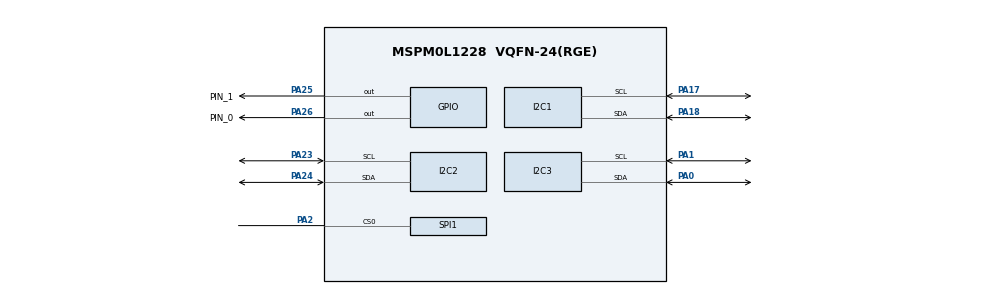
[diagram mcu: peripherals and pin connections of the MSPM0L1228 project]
/**
 * These arguments were used when this file was generated. They will be automatically applied on subsequent loads
 * via the GUI or CLI. Run CLI with '--help' for additional information on how to override these arguments.
 * @cliArgs --device "MSPM0L122X" --part "Default" --package "VQFN-24(RGE)" --product "mspm0_sdk@2.10.00.04"
 * @v2CliArgs --device "MSPM0L1228" --package "VQFN-24(RGE)" --product "mspm0_sdk@2.10.00.04"
 * @versions {"tool":"1.26.2+4477"}
 */

/**
 * Import the modules used in this configuration.
 */
const GPIO   = scripting.addModule("/ti/driverlib/GPIO", {}, false);
const GPIO1  = GPIO.addInstance();
const GPIO2  = GPIO.addInstance();
const I2C    = scripting.addModule("/ti/driverlib/I2C", {}, false);
const I2C1   = I2C.addInstance();
const I2C2   = I2C.addInstance();
const I2C3   = I2C.addInstance();
const SPI    = scripting.addModule("/ti/driverlib/SPI", {}, false);
const SPI1   = SPI.addInstance();
const SYSCTL = scripting.addModule("/ti/driverlib/SYSCTL");

/**
 * Write custom configuration values to the imported modules.
 */
GPIO1.$name                          = "ANT_POW_EN_N";
GPIO1.associatedPins[0].$name        = "PIN_0";
GPIO1.associatedPins[0].initialValue = "SET";
GPIO1.associatedPins[0].pin.$assign  = "PA26";

const Board = scripting.addModule("/ti/driverlib/Board", {}, false);

GPIO2.$name                          = "ANT_IRQ_N";
GPIO2.associatedPins[0].$name        = "PIN_1";
GPIO2.associatedPins[0].initialValue = "SET";
GPIO2.associatedPins[0].pin.$assign  = "PA25";

I2C1.$name                         = "I2C_0";
I2C1.basicEnableController         = true;
I2C1.enableDMAEvent1               = false;
I2C1.enableDMAEvent2               = false;
I2C1.advDigitalGlitchFilter        = "CLOCKS_1";
I2C1.peripheral.$assign            = "I2C1";
I2C1.peripheral.sdaPin.$assign     = "PA18";
I2C1.peripheral.sclPin.$assign     = "PA17";
I2C1.sdaPinConfig.$name            = "ti_driverlib_gpio_GPIOPinGeneric4";
I2C1.sdaPinConfig.enableConfig     = true;
I2C1.sdaPinConfig.internalResistor = "PULL_UP";
I2C1.sclPinConfig.$name            = "ti_driverlib_gpio_GPIOPinGeneric5";
I2C1.sclPinConfig.enableConfig     = true;
I2C1.sclPinConfig.internalResistor = "PULL_UP";

I2C2.$name                         = "I2C_1";
I2C2.basicEnableController         = true;
I2C2.advDigitalGlitchFilter        = "CLOCKS_1";
I2C2.advControllerRXFIFOTRIG       = "BYTES_8";
I2C2.advControllerTXFIFOTRIG       = "BYTES_7";
I2C2.enableDMAEvent1               = false;
I2C2.enableDMAEvent2               = false;
I2C2.peripheral.$assign            = "I2C2";
I2C2.peripheral.sdaPin.$assign     = "PA24";
I2C2.peripheral.sclPin.$assign     = "PA23";
I2C2.sdaPinConfig.$name            = "ti_driverlib_gpio_GPIOPinGeneric6";
I2C2.sdaPinConfig.enableConfig     = true;
I2C2.sdaPinConfig.internalResistor = "PULL_UP";
I2C2.sclPinConfig.$name            = "ti_driverlib_gpio_GPIOPinGeneric7";
I2C2.sclPinConfig.enableConfig     = true;
I2C2.sclPinConfig.internalResistor = "PULL_UP";

I2C3.$name                     = "I2C_2";
I2C3.peripheral.sdaPin.$assign = "PA0";
I2C3.peripheral.sclPin.$assign = "PA1";
I2C3.sdaPinConfig.$name        = "ti_driverlib_gpio_GPIOPinGeneric8";
I2C3.sclPinConfig.$name        = "ti_driverlib_gpio_GPIOPinGeneric9";

SPI1.$name                              = "SPI_0";
SPI1.mode                               = "PERIPHERAL";
SPI1.chipSelect                         = [];
SPI1.enableDMAEvent1                    = false;
SPI1.enableDMAEvent2                    = false;
SPI1.frameFormat                        = "TI_SYNC";
SPI1.peripheral.cs0Pin.$assign          = "PA2";
SPI1.sclkPinConfig.onlyInternalResistor = scripting.forceWrite(false);
SPI1.sclkPinConfig.passedPeripheralType = scripting.forceWrite("Digital");
SPI1.sclkPinConfig.$name                = "ti_driverlib_gpio_GPIOPinGeneric0";
SPI1.mosiPinConfig.hideOutputInversion  = scripting.forceWrite(false);
SPI1.mosiPinConfig.onlyInternalResistor = scripting.forceWrite(false);
SPI1.mosiPinConfig.passedPeripheralType = scripting.forceWrite("Digital");
SPI1.mosiPinConfig.$name                = "ti_driverlib_gpio_GPIOPinGeneric1";
SPI1.misoPinConfig.onlyInternalResistor = scripting.forceWrite(false);
SPI1.misoPinConfig.passedPeripheralType = scripting.forceWrite("Digital");
SPI1.misoPinConfig.$name                = "ti_driverlib_gpio_GPIOPinGeneric2";
SPI1.cs0PinConfig.hideOutputInversion   = scripting.forceWrite(false);
SPI1.cs0PinConfig.onlyInternalResistor  = scripting.forceWrite(false);
SPI1.cs0PinConfig.passedPeripheralType  = scripting.forceWrite("Digital");
SPI1.cs0PinConfig.$name                 = "ti_driverlib_gpio_GPIOPinGeneric3";


const ProjectConfig              = scripting.addModule("/ti/project_config/ProjectConfig", {}, false);
ProjectConfig.migrationCondition = true;

/**
 * Pinmux solution for unlocked pins/peripherals. This ensures that minor changes to the automatic solver in a future
 * version of the tool will not impact the pinmux you originally saw.  These lines can be completely deleted in order to
 * re-solve from scratch.
 */
Board.peripheral.$suggestSolution          = "DEBUGSS";
Board.peripheral.swclkPin.$suggestSolution = "PA20";
Board.peripheral.swdioPin.$suggestSolution = "PA19";
I2C3.peripheral.$suggestSolution           = "I2C0";
SPI1.peripheral.$suggestSolution           = "SPI0";
SPI1.peripheral.sclkPin.$suggestSolution   = "PA11";
SPI1.peripheral.mosiPin.$suggestSolution   = "PA9";
SPI1.peripheral.misoPin.$suggestSolution   = "PA10";
SYSCTL.peripheral.$suggestSolution         = "SYSCTL";
